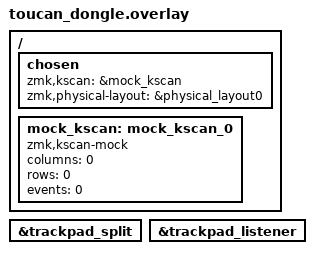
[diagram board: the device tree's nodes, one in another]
#include "toucan.dtsi"


/ {
    chosen {
        zmk,kscan = &mock_kscan;
        zmk,physical-layout = &physical_layout0;
    };

    mock_kscan: mock_kscan_0 {
        compatible = "zmk,kscan-mock";
        columns = <0>;
        rows = <0>;
        events = <0>;
    };
};


&trackpad_split {
    status = "okay";
};


&trackpad_listener {
    status = "okay";
};
